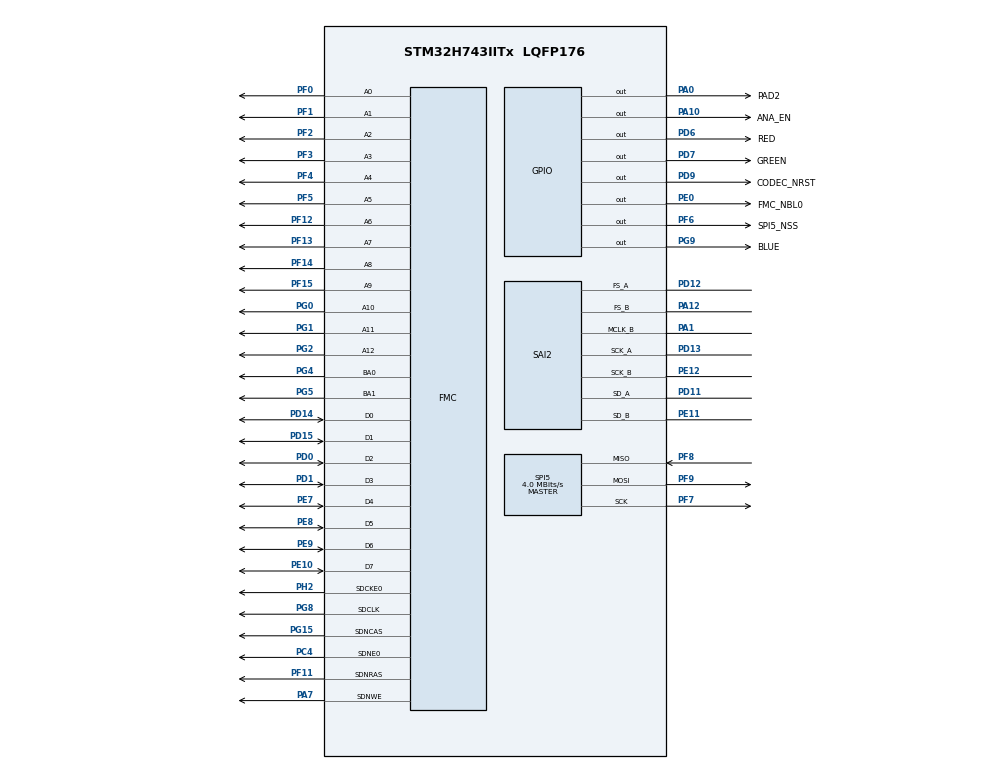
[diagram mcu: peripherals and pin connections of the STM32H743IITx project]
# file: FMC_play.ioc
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Bdma.MEMTOMEM.0.Direction=DMA_MEMORY_TO_MEMORY
Bdma.MEMTOMEM.0.EventEnable=DISABLE
Bdma.MEMTOMEM.0.Instance=BDMA_Channel0
Bdma.MEMTOMEM.0.MemDataAlignment=DMA_MDATAALIGN_BYTE
Bdma.MEMTOMEM.0.MemInc=DMA_MINC_ENABLE
Bdma.MEMTOMEM.0.Mode=DMA_NORMAL
Bdma.MEMTOMEM.0.PeriphDataAlignment=DMA_PDATAALIGN_WORD
Bdma.MEMTOMEM.0.PeriphInc=DMA_PINC_ENABLE
Bdma.MEMTOMEM.0.Polarity=HAL_DMAMUX_REQ_GEN_RISING
Bdma.MEMTOMEM.0.Priority=DMA_PRIORITY_LOW
Bdma.MEMTOMEM.0.RequestNumber=1
Bdma.MEMTOMEM.0.SignalID=HAL_DMAMUX2_REQ_GEN_LPTIM3_WKUP
Bdma.MEMTOMEM.0.SyncEnable=DISABLE
Bdma.MEMTOMEM.0.SyncPolarity=HAL_DMAMUX_SYNC_NO_EVENT
Bdma.MEMTOMEM.0.SyncRequestNumber=1
Bdma.MEMTOMEM.0.SyncSignalID=HAL_DMAMUX2_SYNC_LPTIM3_OUT
Bdma.Request0=MEMTOMEM
Bdma.RequestsNb=1
CORTEX_M7.CPU_DCache=Disabled
CORTEX_M7.CPU_ICache=Disabled
Dma.MEMTOMEM.0.Direction=DMA_MEMORY_TO_MEMORY
Dma.MEMTOMEM.0.EventEnable=DISABLE
Dma.MEMTOMEM.0.FIFOMode=DMA_FIFOMODE_ENABLE
Dma.MEMTOMEM.0.FIFOThreshold=DMA_FIFO_THRESHOLD_FULL
Dma.MEMTOMEM.0.Instance=DMA1_Stream2
Dma.MEMTOMEM.0.MemBurst=DMA_MBURST_SINGLE
Dma.MEMTOMEM.0.MemDataAlignment=DMA_MDATAALIGN_BYTE
Dma.MEMTOMEM.0.MemInc=DMA_MINC_DISABLE
Dma.MEMTOMEM.0.Mode=DMA_NORMAL
Dma.MEMTOMEM.0.PeriphBurst=DMA_PBURST_SINGLE
Dma.MEMTOMEM.0.PeriphDataAlignment=DMA_PDATAALIGN_BYTE
Dma.MEMTOMEM.0.PeriphInc=DMA_PINC_DISABLE
Dma.MEMTOMEM.0.Polarity=HAL_DMAMUX_REQ_GEN_RISING
Dma.MEMTOMEM.0.Priority=DMA_PRIORITY_VERY_HIGH
Dma.MEMTOMEM.0.RequestNumber=1
Dma.MEMTOMEM.0.SignalID=HAL_DMAMUX1_REQ_GEN_LPTIM3_OUT
Dma.MEMTOMEM.0.SyncEnable=DISABLE
Dma.MEMTOMEM.0.SyncPolarity=HAL_DMAMUX_SYNC_NO_EVENT
Dma.MEMTOMEM.0.SyncRequestNumber=1
Dma.MEMTOMEM.0.SyncSignalID=HAL_DMAMUX1_SYNC_LPTIM3_OUT
Dma.Request0=MEMTOMEM
Dma.Request1=SAI2_A
Dma.Request2=SAI2_B
Dma.SAI2_A.1.Direction=DMA_PERIPH_TO_MEMORY
Dma.SAI2_A.1.EventEnable=DISABLE
Dma.SAI2_A.1.FIFOMode=DMA_FIFOMODE_ENABLE
Dma.SAI2_A.1.FIFOThreshold=DMA_FIFO_THRESHOLD_FULL
Dma.SAI2_A.1.Instance=DMA1_Stream0
Dma.SAI2_A.1.MemBurst=DMA_MBURST_SINGLE
Dma.SAI2_A.1.MemDataAlignment=DMA_MDATAALIGN_WORD
Dma.SAI2_A.1.MemInc=DMA_MINC_ENABLE
Dma.SAI2_A.1.Mode=DMA_CIRCULAR
Dma.SAI2_A.1.PeriphBurst=DMA_PBURST_SINGLE
Dma.SAI2_A.1.PeriphDataAlignment=DMA_PDATAALIGN_WORD
Dma.SAI2_A.1.PeriphInc=DMA_PINC_DISABLE
Dma.SAI2_A.1.Polarity=HAL_DMAMUX_REQ_GEN_RISING
Dma.SAI2_A.1.Priority=DMA_PRIORITY_HIGH
Dma.SAI2_A.1.RequestNumber=1
Dma.SAI2_A.1.SignalID=HAL_DMAMUX1_REQ_GEN_LPTIM3_OUT
Dma.SAI2_A.1.SyncEnable=DISABLE
Dma.SAI2_A.1.SyncPolarity=HAL_DMAMUX_SYNC_NO_EVENT
Dma.SAI2_A.1.SyncRequestNumber=1
Dma.SAI2_A.1.SyncSignalID=HAL_DMAMUX1_SYNC_LPTIM3_OUT
Dma.SAI2_B.2.Direction=DMA_MEMORY_TO_PERIPH
Dma.SAI2_B.2.EventEnable=DISABLE
Dma.SAI2_B.2.FIFOMode=DMA_FIFOMODE_ENABLE
Dma.SAI2_B.2.FIFOThreshold=DMA_FIFO_THRESHOLD_FULL
Dma.SAI2_B.2.Instance=DMA1_Stream1
Dma.SAI2_B.2.MemBurst=DMA_MBURST_SINGLE
Dma.SAI2_B.2.MemDataAlignment=DMA_MDATAALIGN_WORD
Dma.SAI2_B.2.MemInc=DMA_MINC_ENABLE
Dma.SAI2_B.2.Mode=DMA_CIRCULAR
Dma.SAI2_B.2.PeriphBurst=DMA_PBURST_SINGLE
Dma.SAI2_B.2.PeriphDataAlignment=DMA_PDATAALIGN_WORD
Dma.SAI2_B.2.PeriphInc=DMA_PINC_DISABLE
Dma.SAI2_B.2.Polarity=HAL_DMAMUX_REQ_GEN_RISING
Dma.SAI2_B.2.Priority=DMA_PRIORITY_HIGH
Dma.SAI2_B.2.RequestNumber=1
Dma.SAI2_B.2.SignalID=HAL_DMAMUX1_REQ_GEN_LPTIM3_OUT
Dma.SAI2_B.2.SyncEnable=DISABLE
Dma.SAI2_B.2.SyncPolarity=HAL_DMAMUX_SYNC_NO_EVENT
Dma.SAI2_B.2.SyncRequestNumber=1
Dma.SAI2_B.2.SyncSignalID=HAL_DMAMUX1_SYNC_LPTIM3_OUT
FMC.CASLatency1=FMC_SDRAM_CAS_LATENCY_2
FMC.ColumnBitsNumber1=FMC_SDRAM_COLUMN_BITS_NUM_10
FMC.ExitSelfRefreshDelay1=7
FMC.LoadToActiveDelay1=2
FMC.RCDDelay1=2
FMC.RPDelay1=2
FMC.RPDelay2=2
FMC.ReadBurst1=FMC_SDRAM_RBURST_ENABLE
FMC.ReadBurst2=FMC_SDRAM_RBURST_ENABLE
FMC.RowCycleDelay1=6
FMC.RowCycleDelay2=6
FMC.SDClockPeriod1=FMC_SDRAM_CLOCK_PERIOD_2
FMC.SDClockPeriod2=FMC_SDRAM_CLOCK_PERIOD_2
FMC.SelfRefreshTime1=5
FMC.WriteRecoveryTime1=3
Mcu.Family=STM32H7
Mcu.Name=STM32H743IITx
Mcu.Package=LQFP176
NVIC.DMA1_Stream0_IRQn=true\:0\:0\:false\:false\:true\:false\:true
NVIC.DMA1_Stream1_IRQn=true\:0\:0\:false\:false\:true\:false\:true
NVIC.FMC_IRQn=true\:0\:0\:false\:false\:true\:true\:true
NVIC.LPTIM5_IRQn=true\:0\:0\:false\:false\:true\:true\:true
NVIC.PriorityGroup=NVIC_PRIORITYGROUP_4
NVIC.SAI2_IRQn=true\:0\:0\:false\:false\:true\:true\:true
NVIC.SPI5_IRQn=true\:0\:0\:false\:false\:true\:true\:true
PA0-WKUP.GPIO_Label=PAD2
PA0-WKUP.Signal=GPIO_Output
PA1.GPIO_Speed=GPIO_SPEED_FREQ_VERY_HIGH
PA1.Mode=SAI_B_MasterWithClock
PA1.Signal=SAI2_MCLK_B
PA10.GPIO_Label=ANA_EN
PA10.Signal=GPIO_Output
PA12.GPIO_Speed=GPIO_SPEED_FREQ_VERY_HIGH
PA12.Mode=SAI_B_MasterWithClock
PA12.Signal=SAI2_FS_B
PA7.Signal=FMC_SDNWE
PC14-OSC32_IN.Mode=LSE-External-Oscillator
PC14-OSC32_IN.Signal=RCC_OSC32_IN
PC15-OSC32_OUT.Mode=LSE-External-Oscillator
PC15-OSC32_OUT.Signal=RCC_OSC32_OUT
PC4.Mode=SdramChipSelect1_1
PC4.Signal=FMC_SDNE0
PD0.Signal=FMC_D2_DA2
PD1.Signal=FMC_D3_DA3
PD11.GPIO_Speed=GPIO_SPEED_FREQ_VERY_HIGH
PD11.Mode=SAI_A_Master
PD11.Signal=SAI2_SD_A
PD12.GPIO_Speed=GPIO_SPEED_FREQ_VERY_HIGH
PD12.Mode=SAI_A_Master
PD12.Signal=SAI2_FS_A
PD13.GPIO_Speed=GPIO_SPEED_FREQ_VERY_HIGH
PD13.Mode=SAI_A_Master
PD13.Signal=SAI2_SCK_A
PD14.Signal=FMC_D0_DA0
PD15.Signal=FMC_D1_DA1
PD6.GPIO_Label=RED
PD6.Signal=GPIO_Output
PD7.GPIO_Label=GREEN
PD7.Signal=GPIO_Output
PD9.GPIO_Label=CODEC_NRST
PD9.Signal=GPIO_Output
PE0.GPIO_Label=FMC_NBL0
PE0.Signal=GPIO_Output
PE10.Signal=FMC_D7_DA7
PE11.GPIO_Speed=GPIO_SPEED_FREQ_VERY_HIGH
PE11.Mode=SAI_B_MasterWithClock
PE11.Signal=SAI2_SD_B
PE12.GPIO_Speed=GPIO_SPEED_FREQ_VERY_HIGH
PE12.Mode=SAI_B_MasterWithClock
PE12.Signal=SAI2_SCK_B
PE7.Signal=FMC_D4_DA4
PE8.Signal=FMC_D5_DA5
PE9.Signal=FMC_D6_DA6
PF0.Signal=FMC_A0
PF1.Signal=FMC_A1
PF11.Signal=FMC_SDNRAS
PF12.Signal=FMC_A6
PF13.Signal=FMC_A7
PF14.Signal=FMC_A8
PF15.Signal=FMC_A9
PF2.Signal=FMC_A2
PF3.Signal=FMC_A3
PF4.Signal=FMC_A4
PF5.Signal=FMC_A5
PF6.GPIO_Label=SPI5_NSS
PF6.Signal=GPIO_Output
PF7.Mode=Full_Duplex_Master
PF7.Signal=SPI5_SCK
PF8.Mode=Full_Duplex_Master
PF8.Signal=SPI5_MISO
PF9.Mode=Full_Duplex_Master
PF9.Signal=SPI5_MOSI
PG0.Signal=FMC_A10
PG1.Signal=FMC_A11
PG15.Signal=FMC_SDNCAS
PG2.Signal=FMC_A12
PG4.Signal=FMC_A14_BA0
PG5.Signal=FMC_A15_BA1
PG8.Signal=FMC_SDCLK
PG9.GPIO_Label=BLUE
PG9.Signal=GPIO_Output
PH0-OSC_IN.Mode=HSE-External-Oscillator
PH0-OSC_IN.Signal=RCC_OSC_IN
PH1-OSC_OUT.Mode=HSE-External-Oscillator
PH1-OSC_OUT.Signal=RCC_OSC_OUT
PH2.Mode=SdramChipSelect1_1
PH2.Signal=FMC_SDCKE0
ProjectManager.HeapSize=0x200
ProjectManager.StackSize=0x400
ProjectManager.TargetToolchain=TrueSTUDIO
RCC.ADCFreq_Value=393000000
RCC.APB1Freq_Value=100000000
RCC.APB2Freq_Value=100000000
RCC.APB3Freq_Value=100000000
RCC.APB4Freq_Value=100000000
RCC.CortexFreq_Value=400000000
RCC.D1PPRE=RCC_APB3_DIV2
RCC.D2PPRE1=RCC_APB1_DIV2
RCC.D2PPRE2=RCC_APB2_DIV2
RCC.D3PPRE=RCC_APB4_DIV2
RCC.DIVM1=1
RCC.DIVM2=8
RCC.DIVN1=50
RCC.DIVN2=393
RCC.DIVQ1=4
RCC.DIVR2=8
RCC.HCLKFreq_Value=200000000
RCC.HPRE=RCC_HCLK_DIV2
RCC.HRTIMCLockSelection=RCC_HRTIM1CLK_CPUCLK
RCC.HSE_VALUE=16000000
RCC.PLLSourceVirtual=RCC_PLLSOURCE_HSE
RCC.SAI23CLockSelection=RCC_SAI23CLKSOURCE_PLL2
RCC.SYSCLKFreq_VALUE=400000000
RCC.SYSCLKSource=RCC_SYSCLKSOURCE_PLLCLK
RCC.Spi45ClockSelection=RCC_SPI45CLKSOURCE_HSE
RCC.USBFreq_Value=200000000
SAI2.ActiveFrameLength-SAI_A_Master=1
SAI2.AudioFrequency-SAI_A_Master=SAI_AUDIO_FREQUENCY_96K
SAI2.AudioFrequency-SAI_B_MasterWithClock=SAI_AUDIO_FREQUENCY_96K
SAI2.AudioMode-SAI_A_Master=SAI_MODEMASTER_RX
SAI2.ClockStrobing-SAI_A_Master=SAI_CLOCKSTROBING_FALLINGEDGE
SAI2.ClockStrobing-SAI_B_MasterWithClock=SAI_CLOCKSTROBING_RISINGEDGE
SAI2.DataSize-SAI_A_Master=SAI_DATASIZE_32
SAI2.DataSize-SAI_B_MasterWithClock=SAI_DATASIZE_32
SAI2.ErrorAudioFreq-SAI_A_Master=-0.05 %
SAI2.ErrorAudioFreq-SAI_B_MasterWithClock=-0.05 %
SAI2.FIFOThreshold-SAI_A_Master=SAI_FIFOTHRESHOLD_FULL
SAI2.FIFOThreshold-SAI_B_MasterWithClock=SAI_FIFOTHRESHOLD_FULL
SAI2.FSPolarity-SAI_A_Master=SAI_FS_ACTIVE_HIGH
SAI2.FSPolarity-SAI_B_MasterWithClock=SAI_FS_ACTIVE_HIGH
SAI2.FrameLength-SAI_A_Master=256
SAI2.FrameLength-SAI_B_MasterWithClock=256
SAI2.Instance-SAI_A_Master=SAI$Index_Block_A
SAI2.Instance-SAI_B_MasterWithClock=SAI$Index_Block_B
SAI2.MClockEnable-SAI_A_Master=SAI_MASTERCLOCK_DISABLE
SAI2.MClockEnable-SAI_B_MasterWithClock=SAI_MASTERCLOCK_ENABLE
SAI2.MonoStereoMode-SAI_A_Master=SAI_STEREOMODE
SAI2.NoDivider-SAI_A_Master=SAI_MASTERDIVIDER_ENABLE
SAI2.OutputDrive-SAI_A_Master=SAI_OUTPUTDRIVE_ENABLE
SAI2.OutputDrive-SAI_B_MasterWithClock=SAI_OUTPUTDRIVE_ENABLE
SAI2.RealAudioFreq-SAI_A_Master=95.947 KHz
SAI2.RealAudioFreq-SAI_B_MasterWithClock=95.947 KHz
SAI2.SlotActive-SAI_A_Master=0x000000FF
SAI2.SlotActive-SAI_B_MasterWithClock=0x000000FF
SAI2.SlotNumber-SAI_A_Master=8
SAI2.SlotNumber-SAI_B_MasterWithClock=8
SAI2.SlotSize-SAI_A_Master=SAI_SLOTSIZE_DATASIZE
SAI2.Synchro-SAI_A_Master=SAI_ASYNCHRONOUS
SAI2.Synchro-SAI_B_MasterWithClock=SAI_ASYNCHRONOUS
SAI2.SynchroExt-SAI_A_Master=SAI_SYNCEXT_OUTBLOCKB_ENABLE
SAI2.VirtualMode-SAI_A_Master=VM_MASTER
SAI2.VirtualMode-SAI_B_MasterWithClock=VM_MASTER
SAI2.VirtualSlotActive-SAI_A_Master=SAI_SLOT_USERSETTING
SAI2.VirtualSlotActive-SAI_B_MasterWithClock=SAI_SLOT_USERSETTING
SAI2.VirtualSlotActive0-SAI_A_Master=true
SAI2.VirtualSlotActive0-SAI_B_MasterWithClock=true
SAI2.VirtualSlotActive1-SAI_A_Master=true
SAI2.VirtualSlotActive1-SAI_B_MasterWithClock=true
SAI2.VirtualSlotActive2-SAI_A_Master=true
SAI2.VirtualSlotActive2-SAI_B_MasterWithClock=true
SAI2.VirtualSlotActive3-SAI_A_Master=true
SAI2.VirtualSlotActive3-SAI_B_MasterWithClock=true
SAI2.VirtualSlotActive4-SAI_A_Master=true
SAI2.VirtualSlotActive4-SAI_B_MasterWithClock=true
SAI2.VirtualSlotActive5-SAI_A_Master=true
SAI2.VirtualSlotActive5-SAI_B_MasterWithClock=true
SAI2.VirtualSlotActive6-SAI_A_Master=true
SAI2.VirtualSlotActive6-SAI_B_MasterWithClock=true
SAI2.VirtualSlotActive7-SAI_A_Master=true
SAI2.VirtualSlotActive7-SAI_B_MasterWithClock=true
SH.FMC_A0.0=FMC_A0,13b-sda1
SH.FMC_A1.0=FMC_A1,13b-sda1
SH.FMC_A10.0=FMC_A10,13b-sda1
SH.FMC_A11.0=FMC_A11,13b-sda1
SH.FMC_A12.0=FMC_A12,13b-sda1
SH.FMC_A14_BA0.0=FMC_BA0,FourSdramBanks1
SH.FMC_A15_BA1.0=FMC_BA1,FourSdramBanks1
SH.FMC_A2.0=FMC_A2,13b-sda1
SH.FMC_A3.0=FMC_A3,13b-sda1
SH.FMC_A4.0=FMC_A4,13b-sda1
SH.FMC_A5.0=FMC_A5,13b-sda1
SH.FMC_A6.0=FMC_A6,13b-sda1
SH.FMC_A7.0=FMC_A7,13b-sda1
SH.FMC_A8.0=FMC_A8,13b-sda1
SH.FMC_A9.0=FMC_A9,13b-sda1
SH.FMC_D0_DA0.0=FMC_D0,sd-8b-d1
SH.FMC_D1_DA1.0=FMC_D1,sd-8b-d1
SH.FMC_D2_DA2.0=FMC_D2,sd-8b-d1
SH.FMC_D3_DA3.0=FMC_D3,sd-8b-d1
SH.FMC_D4_DA4.0=FMC_D4,sd-8b-d1
SH.FMC_D5_DA5.0=FMC_D5,sd-8b-d1
SH.FMC_D6_DA6.0=FMC_D6,sd-8b-d1
SH.FMC_D7_DA7.0=FMC_D7,sd-8b-d1
SH.FMC_SDCLK.0=FMC_SDCLK,13b-sda1
SH.FMC_SDNCAS.0=FMC_SDNCAS,13b-sda1
SH.FMC_SDNRAS.0=FMC_SDNRAS,13b-sda1
SH.FMC_SDNWE.0=FMC_SDNWE,13b-sda1
SPI5.BaudRatePrescaler=SPI_BAUDRATEPRESCALER_4
SPI5.CLKPhase=SPI_PHASE_2EDGE
SPI5.CLKPolarity=SPI_POLARITY_LOW
SPI5.CalculateBaudRate=4.0 MBits/s
SPI5.DataSize=SPI_DATASIZE_8BIT
SPI5.Direction=SPI_DIRECTION_2LINES
SPI5.FifoThreshold=SPI_FIFO_THRESHOLD_08DATA
SPI5.FirstBit=SPI_FIRSTBIT_MSB
SPI5.Mode=SPI_MODE_MASTER
SPI5.VirtualType=VM_MASTER
VP_LPTIM3_VS_LPTIM_counterModeInternalClock.Mode=Counts__internal_clock_event_00
VP_LPTIM5_VS_LPTIM_counterModeInternalClock.Mode=Counts__internal_clock_event_00
board=Firmware_v0.0

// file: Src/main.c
/**
  ******************************************************************************
  * @file           : main.c
  * @brief          : Main program body
  ******************************************************************************
  ** This notice applies to any and all portions of this file
  * that are not between comment pairs USER CODE BEGIN and
  * USER CODE END. Other portions of this file, whether
  * inserted by the user or by software development tools
  * are owned by their respective copyright owners.
  *
  * COPYRIGHT(c) 2019 STMicroelectronics
  *
  * Redistribution and use in source and binary forms, with or without modification,
  * are permitted provided that the following conditions are met:
  *   1. Redistributions of source code must retain the above copyright notice,
  *      this list of conditions and the following disclaimer.
  *   2. Redistributions in binary form must reproduce the above copyright notice,
  *      this list of conditions and the following disclaimer in the documentation
  *      and/or other materials provided with the distribution.
  *   3. Neither the name of STMicroelectronics nor the names of its contributors
  *      may be used to endorse or promote products derived from this software
  *      without specific prior written permission.
  *
  * THIS SOFTWARE IS PROVIDED BY THE COPYRIGHT HOLDERS AND CONTRIBUTORS "AS IS"
  * AND ANY EXPRESS OR IMPLIED WARRANTIES, INCLUDING, BUT NOT LIMITED TO, THE
  * IMPLIED WARRANTIES OF MERCHANTABILITY AND FITNESS FOR A PARTICULAR PURPOSE ARE
  * DISCLAIMED. IN NO EVENT SHALL THE COPYRIGHT HOLDER OR CONTRIBUTORS BE LIABLE
  * FOR ANY DIRECT, INDIRECT, INCIDENTAL, SPECIAL, EXEMPLARY, OR CONSEQUENTIAL
  * DAMAGES (INCLUDING, BUT NOT LIMITED TO, PROCUREMENT OF SUBSTITUTE GOODS OR
  * SERVICES; LOSS OF USE, DATA, OR PROFITS; OR BUSINESS INTERRUPTION) HOWEVER
  * CAUSED AND ON ANY THEORY OF LIABILITY, WHETHER IN CONTRACT, STRICT LIABILITY,
  * OR TORT (INCLUDING NEGLIGENCE OR OTHERWISE) ARISING IN ANY WAY OUT OF THE USE
  * OF THIS SOFTWARE, EVEN IF ADVISED OF THE POSSIBILITY OF SUCH DAMAGE.
  *
  ******************************************************************************
  */
#include "main.h"
#include "stm32h7xx_hal.h"

/* USER CODE BEGIN Includes */
#include "SDRAM.h"
/* USER CODE END Includes */

LPTIM_HandleTypeDef hlptim3;
LPTIM_HandleTypeDef hlptim5;

SAI_HandleTypeDef hsai_BlockA2;
SAI_HandleTypeDef hsai_BlockB2;
DMA_HandleTypeDef hdma_sai2_a;
DMA_HandleTypeDef hdma_sai2_b;

SPI_HandleTypeDef hspi5;

DMA_HandleTypeDef hdma_memtomem_bdma_channel0;
DMA_HandleTypeDef hdma_memtomem_dma1_stream2;
SDRAM_HandleTypeDef hsdram1;

/* USER CODE BEGIN PV */
/* Private variables ---------------------------------------------------------*/

/* USER CODE END PV */

void SystemClock_Config(void);
static void MX_GPIO_Init(void);
static void MX_BDMA_Init(void);
static void MX_DMA_Init(void);
static void MX_FMC_Init(void);
static void MX_SAI2_Init(void);
static void MX_SPI5_Init(void);
static void MX_LPTIM5_Init(void);
static void MX_LPTIM3_Init(void);

/* USER CODE BEGIN PFP */
/* Private function prototypes -----------------------------------------------*/

/* USER CODE END PFP */

int main(void)
{

  /* MCU Configuration----------------------------------------------------------*/

  /* Reset of all peripherals, Initializes the Flash interface and the Systick. */
  HAL_Init();

  /* Configure the system clock */
  SystemClock_Config();

  /* Initialize all configured peripherals */
  MX_GPIO_Init();
  MX_BDMA_Init();
  MX_DMA_Init();
  MX_FMC_Init();
  MX_SAI2_Init();
  MX_SPI5_Init();
  MX_LPTIM5_Init();
  MX_LPTIM3_Init();
  /* USER CODE BEGIN 2 */
  SDRAM_Init(&hsdram1);
  SDRAM_Clear();

  /* USER CODE END 2 */

  /* Infinite loop */
  while (1)
  {

  }

}

void SystemClock_Config(void)
{

  RCC_OscInitTypeDef RCC_OscInitStruct;
  RCC_ClkInitTypeDef RCC_ClkInitStruct;
  RCC_PeriphCLKInitTypeDef PeriphClkInitStruct;

    /**Supply configuration update enable
    */
  MODIFY_REG(PWR->CR3, PWR_CR3_SCUEN, 0);

    /**Configure the main internal regulator output voltage
    */
  __HAL_PWR_VOLTAGESCALING_CONFIG(PWR_REGULATOR_VOLTAGE_SCALE1);

  while ((PWR->D3CR & (PWR_D3CR_VOSRDY)) != PWR_D3CR_VOSRDY)
  {

  }
    /**Macro to configure the PLL clock source
    */
  __HAL_RCC_PLL_PLLSOURCE_CONFIG(RCC_PLLSOURCE_HSE);

    /**Initializes the CPU, AHB and APB busses clocks
    */
  RCC_OscInitStruct.OscillatorType = RCC_OSCILLATORTYPE_HSE;
  RCC_OscInitStruct.HSEState = RCC_HSE_ON;
  RCC_OscInitStruct.PLL.PLLState = RCC_PLL_ON;
  RCC_OscInitStruct.PLL.PLLSource = RCC_PLLSOURCE_HSE;
  RCC_OscInitStruct.PLL.PLLM = 1;
  RCC_OscInitStruct.PLL.PLLN = 50;
  RCC_OscInitStruct.PLL.PLLP = 2;
  RCC_OscInitStruct.PLL.PLLQ = 4;
  RCC_OscInitStruct.PLL.PLLR = 2;
  RCC_OscInitStruct.PLL.PLLRGE = RCC_PLL1VCIRANGE_3;
  RCC_OscInitStruct.PLL.PLLVCOSEL = RCC_PLL1VCOWIDE;
  RCC_OscInitStruct.PLL.PLLFRACN = 0;
  if (HAL_RCC_OscConfig(&RCC_OscInitStruct) != HAL_OK)
  {
    _Error_Handler(__FILE__, __LINE__);
  }

    /**Initializes the CPU, AHB and APB busses clocks
    */
  RCC_ClkInitStruct.ClockType = RCC_CLOCKTYPE_HCLK|RCC_CLOCKTYPE_SYSCLK
                              |RCC_CLOCKTYPE_PCLK1|RCC_CLOCKTYPE_PCLK2
                              |RCC_CLOCKTYPE_D3PCLK1|RCC_CLOCKTYPE_D1PCLK1;
  RCC_ClkInitStruct.SYSCLKSource = RCC_SYSCLKSOURCE_PLLCLK;
  RCC_ClkInitStruct.SYSCLKDivider = RCC_SYSCLK_DIV1;
  RCC_ClkInitStruct.AHBCLKDivider = RCC_HCLK_DIV2;
  RCC_ClkInitStruct.APB3CLKDivider = RCC_APB3_DIV2;
  RCC_ClkInitStruct.APB1CLKDivider = RCC_APB1_DIV2;
  RCC_ClkInitStruct.APB2CLKDivider = RCC_APB2_DIV2;
  RCC_ClkInitStruct.APB4CLKDivider = RCC_APB4_DIV2;

  if (HAL_RCC_ClockConfig(&RCC_ClkInitStruct, FLASH_LATENCY_2) != HAL_OK)
  {
    _Error_Handler(__FILE__, __LINE__);
  }

  PeriphClkInitStruct.PeriphClockSelection = RCC_PERIPHCLK_SPI5|RCC_PERIPHCLK_SAI2
                              |RCC_PERIPHCLK_LPTIM5|RCC_PERIPHCLK_LPTIM3
                              |RCC_PERIPHCLK_FMC;
  PeriphClkInitStruct.PLL2.PLL2M = 8;
  PeriphClkInitStruct.PLL2.PLL2N = 393;
  PeriphClkInitStruct.PLL2.PLL2P = 2;
  PeriphClkInitStruct.PLL2.PLL2Q = 2;
  PeriphClkInitStruct.PLL2.PLL2R = 8;
  PeriphClkInitStruct.PLL2.PLL2RGE = RCC_PLL2VCIRANGE_1;
  PeriphClkInitStruct.PLL2.PLL2VCOSEL = RCC_PLL2VCOWIDE;
  PeriphClkInitStruct.PLL2.PLL2FRACN = 0;
  PeriphClkInitStruct.FmcClockSelection = RCC_FMCCLKSOURCE_D1HCLK;
  PeriphClkInitStruct.Sai23ClockSelection = RCC_SAI23CLKSOURCE_PLL2;
  PeriphClkInitStruct.Spi45ClockSelection = RCC_SPI45CLKSOURCE_HSE;
  PeriphClkInitStruct.Lptim345ClockSelection = RCC_LPTIM345CLKSOURCE_D3PCLK1;
  if (HAL_RCCEx_PeriphCLKConfig(&PeriphClkInitStruct) != HAL_OK)
  {
    _Error_Handler(__FILE__, __LINE__);
  }

    /**Configure the Systick interrupt time
    */
  HAL_SYSTICK_Config(SystemCoreClock/1000);

    /**Configure the Systick
    */
  HAL_SYSTICK_CLKSourceConfig(SYSTICK_CLKSOURCE_HCLK);

  /* SysTick_IRQn interrupt configuration */
  HAL_NVIC_SetPriority(SysTick_IRQn, 0, 0);
}

/* LPTIM3 init function */
static void MX_LPTIM3_Init(void)
{

  hlptim3.Instance = LPTIM3;
  hlptim3.Init.Clock.Source = LPTIM_CLOCKSOURCE_APBCLOCK_LPOSC;
  hlptim3.Init.Clock.Prescaler = LPTIM_PRESCALER_DIV1;
  hlptim3.Init.Trigger.Source = LPTIM_TRIGSOURCE_SOFTWARE;
  hlptim3.Init.OutputPolarity = LPTIM_OUTPUTPOLARITY_HIGH;
  hlptim3.Init.UpdateMode = LPTIM_UPDATE_IMMEDIATE;
  hlptim3.Init.CounterSource = LPTIM_COUNTERSOURCE_INTERNAL;
  hlptim3.Init.Input1Source = LPTIM_INPUT1SOURCE_GPIO;
  if (HAL_LPTIM_Init(&hlptim3) != HAL_OK)
  {
    _Error_Handler(__FILE__, __LINE__);
  }

}

/* LPTIM5 init function */
static void MX_LPTIM5_Init(void)
{

  hlptim5.Instance = LPTIM5;
  hlptim5.Init.Clock.Source = LPTIM_CLOCKSOURCE_APBCLOCK_LPOSC;
  hlptim5.Init.Clock.Prescaler = LPTIM_PRESCALER_DIV1;
  hlptim5.Init.Trigger.Source = LPTIM_TRIGSOURCE_SOFTWARE;
  hlptim5.Init.OutputPolarity = LPTIM_OUTPUTPOLARITY_HIGH;
  hlptim5.Init.UpdateMode = LPTIM_UPDATE_IMMEDIATE;
  hlptim5.Init.CounterSource = LPTIM_COUNTERSOURCE_INTERNAL;
  if (HAL_LPTIM_Init(&hlptim5) != HAL_OK)
  {
    _Error_Handler(__FILE__, __LINE__);
  }

}

/* SAI2 init function */
static void MX_SAI2_Init(void)
{

  hsai_BlockA2.Instance = SAI2_Block_A;
  hsai_BlockA2.Init.Protocol = SAI_FREE_PROTOCOL;
  hsai_BlockA2.Init.AudioMode = SAI_MODEMASTER_RX;
  hsai_BlockA2.Init.DataSize = SAI_DATASIZE_32;
  hsai_BlockA2.Init.FirstBit = SAI_FIRSTBIT_MSB;
  hsai_BlockA2.Init.ClockStrobing = SAI_CLOCKSTROBING_FALLINGEDGE;
  hsai_BlockA2.Init.Synchro = SAI_ASYNCHRONOUS;
  hsai_BlockA2.Init.OutputDrive = SAI_OUTPUTDRIVE_ENABLE;
  hsai_BlockA2.Init.NoDivider = SAI_MASTERDIVIDER_ENABLE;
  hsai_BlockA2.Init.FIFOThreshold = SAI_FIFOTHRESHOLD_FULL;
  hsai_BlockA2.Init.AudioFrequency = SAI_AUDIO_FREQUENCY_96K;
  hsai_BlockA2.Init.SynchroExt = SAI_SYNCEXT_OUTBLOCKB_ENABLE;
  hsai_BlockA2.Init.MonoStereoMode = SAI_STEREOMODE;
  hsai_BlockA2.Init.CompandingMode = SAI_NOCOMPANDING;
  hsai_BlockA2.Init.PdmInit.Activation = DISABLE;
  hsai_BlockA2.Init.PdmInit.MicPairsNbr = 0;
  hsai_BlockA2.Init.PdmInit.ClockEnable = SAI_PDM_CLOCK1_ENABLE;
  hsai_BlockA2.FrameInit.FrameLength = 256;
  hsai_BlockA2.FrameInit.ActiveFrameLength = 1;
  hsai_BlockA2.FrameInit.FSDefinition = SAI_FS_STARTFRAME;
  hsai_BlockA2.FrameInit.FSPolarity = SAI_FS_ACTIVE_HIGH;
  hsai_BlockA2.FrameInit.FSOffset = SAI_FS_FIRSTBIT;
  hsai_BlockA2.SlotInit.FirstBitOffset = 0;
  hsai_BlockA2.SlotInit.SlotSize = SAI_SLOTSIZE_DATASIZE;
  hsai_BlockA2.SlotInit.SlotNumber = 8;
  hsai_BlockA2.SlotInit.SlotActive = 0x000000FF;
  if (HAL_SAI_Init(&hsai_BlockA2) != HAL_OK)
  {
    _Error_Handler(__FILE__, __LINE__);
  }

  hsai_BlockB2.Instance = SAI2_Block_B;
  hsai_BlockB2.Init.Protocol = SAI_FREE_PROTOCOL;
  hsai_BlockB2.Init.AudioMode = SAI_MODEMASTER_TX;
  hsai_BlockB2.Init.DataSize = SAI_DATASIZE_32;
  hsai_BlockB2.Init.FirstBit = SAI_FIRSTBIT_MSB;
  hsai_BlockB2.Init.ClockStrobing = SAI_CLOCKSTROBING_RISINGEDGE;
  hsai_BlockB2.Init.Synchro = SAI_ASYNCHRONOUS;
  hsai_BlockB2.Init.OutputDrive = SAI_OUTPUTDRIVE_ENABLE;
  hsai_BlockB2.Init.NoDivider = SAI_MASTERDIVIDER_ENABLE;
  hsai_BlockB2.Init.FIFOThreshold = SAI_FIFOTHRESHOLD_FULL;
  hsai_BlockB2.Init.AudioFrequency = SAI_AUDIO_FREQUENCY_96K;
  hsai_BlockB2.Init.SynchroExt = SAI_SYNCEXT_DISABLE;
  hsai_BlockB2.Init.MonoStereoMode = SAI_STEREOMODE;
  hsai_BlockB2.Init.CompandingMode = SAI_NOCOMPANDING;
  hsai_BlockB2.Init.TriState = SAI_OUTPUT_NOTRELEASED;
  hsai_BlockB2.Init.PdmInit.Activation = DISABLE;
  hsai_BlockB2.Init.PdmInit.MicPairsNbr = 0;
  hsai_BlockB2.Init.PdmInit.ClockEnable = SAI_PDM_CLOCK1_ENABLE;
  hsai_BlockB2.FrameInit.FrameLength = 256;
  hsai_BlockB2.FrameInit.ActiveFrameLength = 1;
  hsai_BlockB2.FrameInit.FSDefinition = SAI_FS_STARTFRAME;
  hsai_BlockB2.FrameInit.FSPolarity = SAI_FS_ACTIVE_HIGH;
  hsai_BlockB2.FrameInit.FSOffset = SAI_FS_FIRSTBIT;
  hsai_BlockB2.SlotInit.FirstBitOffset = 0;
  hsai_BlockB2.SlotInit.SlotSize = SAI_SLOTSIZE_DATASIZE;
  hsai_BlockB2.SlotInit.SlotNumber = 8;
  hsai_BlockB2.SlotInit.SlotActive = 0x000000FF;
  if (HAL_SAI_Init(&hsai_BlockB2) != HAL_OK)
  {
    _Error_Handler(__FILE__, __LINE__);
  }

}

/* SPI5 init function */
static void MX_SPI5_Init(void)
{

  /* SPI5 parameter configuration*/
  hspi5.Instance = SPI5;
  hspi5.Init.Mode = SPI_MODE_MASTER;
  hspi5.Init.Direction = SPI_DIRECTION_2LINES;
  hspi5.Init.DataSize = SPI_DATASIZE_8BIT;
  hspi5.Init.CLKPolarity = SPI_POLARITY_LOW;
  hspi5.Init.CLKPhase = SPI_PHASE_2EDGE;
  hspi5.Init.NSS = SPI_NSS_SOFT;
  hspi5.Init.BaudRatePrescaler = SPI_BAUDRATEPRESCALER_4;
  hspi5.Init.FirstBit = SPI_FIRSTBIT_MSB;
  hspi5.Init.TIMode = SPI_TIMODE_DISABLE;
  hspi5.Init.CRCCalculation = SPI_CRCCALCULATION_DISABLE;
  hspi5.Init.CRCPolynomial = 7;
  hspi5.Init.NSSPMode = SPI_NSS_PULSE_ENABLE;
  hspi5.Init.NSSPolarity = SPI_NSS_POLARITY_LOW;
  hspi5.Init.FifoThreshold = SPI_FIFO_THRESHOLD_08DATA;
  hspi5.Init.TxCRCInitializationPattern = SPI_CRC_INITIALIZATION_ALL_ZERO_PATTERN;
  hspi5.Init.RxCRCInitializationPattern = SPI_CRC_INITIALIZATION_ALL_ZERO_PATTERN;
  hspi5.Init.MasterSSIdleness = SPI_MASTER_SS_IDLENESS_00CYCLE;
  hspi5.Init.MasterInterDataIdleness = SPI_MASTER_INTERDATA_IDLENESS_00CYCLE;
  hspi5.Init.MasterReceiverAutoSusp = SPI_MASTER_INTERDATA_IDLENESS_00CYCLE;
  hspi5.Init.MasterKeepIOState = SPI_MASTER_KEEP_IO_STATE_DISABLE;
  hspi5.Init.IOSwap = SPI_IO_SWAP_DISABLE;
  if (HAL_SPI_Init(&hspi5) != HAL_OK)
  {
    _Error_Handler(__FILE__, __LINE__);
  }

}

static void MX_BDMA_Init(void)
{
  /* DMA controller clock enable */
  __HAL_RCC_BDMA_CLK_ENABLE();

  /* Configure DMA request hdma_memtomem_bdma_channel0 on BDMA_Channel0 */
  hdma_memtomem_bdma_channel0.Instance = BDMA_Channel0;
  hdma_memtomem_bdma_channel0.Init.Request = BDMA_REQUEST_MEM2MEM;
  hdma_memtomem_bdma_channel0.Init.Direction = DMA_MEMORY_TO_MEMORY;
  hdma_memtomem_bdma_channel0.Init.PeriphInc = DMA_PINC_ENABLE;
  hdma_memtomem_bdma_channel0.Init.MemInc = DMA_MINC_ENABLE;
  hdma_memtomem_bdma_channel0.Init.PeriphDataAlignment = DMA_PDATAALIGN_WORD;
  hdma_memtomem_bdma_channel0.Init.MemDataAlignment = DMA_MDATAALIGN_BYTE;
  hdma_memtomem_bdma_channel0.Init.Mode = DMA_NORMAL;
  hdma_memtomem_bdma_channel0.Init.Priority = DMA_PRIORITY_LOW;
  if (HAL_DMA_Init(&hdma_memtomem_bdma_channel0) != HAL_OK)
  {
    _Error_Handler(__FILE__, __LINE__);
  }

}

static void MX_DMA_Init(void)
{
  /* DMA controller clock enable */
  __HAL_RCC_DMA1_CLK_ENABLE();

  /* Configure DMA request hdma_memtomem_dma1_stream2 on DMA1_Stream2 */
  hdma_memtomem_dma1_stream2.Instance = DMA1_Stream2;
  hdma_memtomem_dma1_stream2.Init.Request = DMA_REQUEST_MEM2MEM;
  hdma_memtomem_dma1_stream2.Init.Direction = DMA_MEMORY_TO_MEMORY;
  hdma_memtomem_dma1_stream2.Init.PeriphInc = DMA_PINC_DISABLE;
  hdma_memtomem_dma1_stream2.Init.MemInc = DMA_MINC_DISABLE;
  hdma_memtomem_dma1_stream2.Init.PeriphDataAlignment = DMA_PDATAALIGN_BYTE;
  hdma_memtomem_dma1_stream2.Init.MemDataAlignment = DMA_MDATAALIGN_BYTE;
  hdma_memtomem_dma1_stream2.Init.Mode = DMA_NORMAL;
  hdma_memtomem_dma1_stream2.Init.Priority = DMA_PRIORITY_VERY_HIGH;
  hdma_memtomem_dma1_stream2.Init.FIFOMode = DMA_FIFOMODE_ENABLE;
  hdma_memtomem_dma1_stream2.Init.FIFOThreshold = DMA_FIFO_THRESHOLD_FULL;
  hdma_memtomem_dma1_stream2.Init.MemBurst = DMA_MBURST_SINGLE;
  hdma_memtomem_dma1_stream2.Init.PeriphBurst = DMA_PBURST_SINGLE;
  if (HAL_DMA_Init(&hdma_memtomem_dma1_stream2) != HAL_OK)
  {
    _Error_Handler(__FILE__, __LINE__);
  }

  /* DMA interrupt init */
  /* DMA1_Stream0_IRQn interrupt configuration */
  HAL_NVIC_SetPriority(DMA1_Stream0_IRQn, 0, 0);
  HAL_NVIC_EnableIRQ(DMA1_Stream0_IRQn);
  /* DMA1_Stream1_IRQn interrupt configuration */
  HAL_NVIC_SetPriority(DMA1_Stream1_IRQn, 0, 0);
  HAL_NVIC_EnableIRQ(DMA1_Stream1_IRQn);

}
/* FMC initialization function */
static void MX_FMC_Init(void)
{
  FMC_SDRAM_TimingTypeDef SdramTiming;

  /** Perform the SDRAM1 memory initialization sequence
  */
  hsdram1.Instance = FMC_SDRAM_DEVICE;
  /* hsdram1.Init */
  hsdram1.Init.SDBank = FMC_SDRAM_BANK1;
  hsdram1.Init.ColumnBitsNumber = FMC_SDRAM_COLUMN_BITS_NUM_10;
  hsdram1.Init.RowBitsNumber = FMC_SDRAM_ROW_BITS_NUM_13;
  hsdram1.Init.MemoryDataWidth = FMC_SDRAM_MEM_BUS_WIDTH_8;
  hsdram1.Init.InternalBankNumber = FMC_SDRAM_INTERN_BANKS_NUM_4;
  hsdram1.Init.CASLatency = FMC_SDRAM_CAS_LATENCY_2;
  hsdram1.Init.WriteProtection = FMC_SDRAM_WRITE_PROTECTION_DISABLE;
  hsdram1.Init.SDClockPeriod = FMC_SDRAM_CLOCK_PERIOD_2;
  hsdram1.Init.ReadBurst = FMC_SDRAM_RBURST_ENABLE;
  hsdram1.Init.ReadPipeDelay = FMC_SDRAM_RPIPE_DELAY_0;
  /* SdramTiming */
  SdramTiming.LoadToActiveDelay = 2;
  SdramTiming.ExitSelfRefreshDelay = 7;
  SdramTiming.SelfRefreshTime = 5;
  SdramTiming.RowCycleDelay = 6;
  SdramTiming.WriteRecoveryTime = 3;
  SdramTiming.RPDelay = 2;
  SdramTiming.RCDDelay = 2;

  if (HAL_SDRAM_Init(&hsdram1, &SdramTiming) != HAL_OK)
  {
    _Error_Handler(__FILE__, __LINE__);
  }

}

/** Configure pins as
        * Analog
        * Input
        * Output
        * EVENT_OUT
        * EXTI
*/
static void MX_GPIO_Init(void)
{

  GPIO_InitTypeDef GPIO_InitStruct;

  /* GPIO Ports Clock Enable */
  __HAL_RCC_GPIOC_CLK_ENABLE();
  __HAL_RCC_GPIOF_CLK_ENABLE();
  __HAL_RCC_GPIOH_CLK_ENABLE();
  __HAL_RCC_GPIOA_CLK_ENABLE();
  __HAL_RCC_GPIOG_CLK_ENABLE();
  __HAL_RCC_GPIOE_CLK_ENABLE();
  __HAL_RCC_GPIOD_CLK_ENABLE();

  /*Configure GPIO pin Output Level */
  HAL_GPIO_WritePin(SPI5_NSS_GPIO_Port, SPI5_NSS_Pin, GPIO_PIN_RESET);

  /*Configure GPIO pin Output Level */
  HAL_GPIO_WritePin(GPIOA, PAD2_Pin|ANA_EN_Pin, GPIO_PIN_RESET);

  /*Configure GPIO pin Output Level */
  HAL_GPIO_WritePin(GPIOD, CODEC_NRST_Pin|RED_Pin|GREEN_Pin, GPIO_PIN_RESET);

  /*Configure GPIO pin Output Level */
  HAL_GPIO_WritePin(BLUE_GPIO_Port, BLUE_Pin, GPIO_PIN_RESET);

  /*Configure GPIO pin Output Level */
  HAL_GPIO_WritePin(FMC_NBL0_GPIO_Port, FMC_NBL0_Pin, GPIO_PIN_RESET);

  /*Configure GPIO pin : SPI5_NSS_Pin */
  GPIO_InitStruct.Pin = SPI5_NSS_Pin;
  GPIO_InitStruct.Mode = GPIO_MODE_OUTPUT_PP;
  GPIO_InitStruct.Pull = GPIO_NOPULL;
  GPIO_InitStruct.Speed = GPIO_SPEED_FREQ_LOW;
  HAL_GPIO_Init(SPI5_NSS_GPIO_Port, &GPIO_InitStruct);

  /*Configure GPIO pins : PAD2_Pin ANA_EN_Pin */
  GPIO_InitStruct.Pin = PAD2_Pin|ANA_EN_Pin;
  GPIO_InitStruct.Mode = GPIO_MODE_OUTPUT_PP;
  GPIO_InitStruct.Pull = GPIO_NOPULL;
  GPIO_InitStruct.Speed = GPIO_SPEED_FREQ_LOW;
  HAL_GPIO_Init(GPIOA, &GPIO_InitStruct);

  /*Configure GPIO pins : CODEC_NRST_Pin RED_Pin GREEN_Pin */
  GPIO_InitStruct.Pin = CODEC_NRST_Pin|RED_Pin|GREEN_Pin;
  GPIO_InitStruct.Mode = GPIO_MODE_OUTPUT_PP;
  GPIO_InitStruct.Pull = GPIO_NOPULL;
  GPIO_InitStruct.Speed = GPIO_SPEED_FREQ_LOW;
  HAL_GPIO_Init(GPIOD, &GPIO_InitStruct);

  /*Configure GPIO pin : BLUE_Pin */
  GPIO_InitStruct.Pin = BLUE_Pin;
  GPIO_InitStruct.Mode = GPIO_MODE_OUTPUT_PP;
  GPIO_InitStruct.Pull = GPIO_NOPULL;
  GPIO_InitStruct.Speed = GPIO_SPEED_FREQ_LOW;
  HAL_GPIO_Init(BLUE_GPIO_Port, &GPIO_InitStruct);

  /*Configure GPIO pin : FMC_NBL0_Pin */
  GPIO_InitStruct.Pin = FMC_NBL0_Pin;
  GPIO_InitStruct.Mode = GPIO_MODE_OUTPUT_PP;
  GPIO_InitStruct.Pull = GPIO_NOPULL;
  GPIO_InitStruct.Speed = GPIO_SPEED_FREQ_LOW;
  HAL_GPIO_Init(FMC_NBL0_GPIO_Port, &GPIO_InitStruct);

}

void _Error_Handler(char *file, int line)
{
  while(1)
  {
  }
}

/************************ (C) COPYRIGHT STMicroelectronics *****END OF FILE****/
